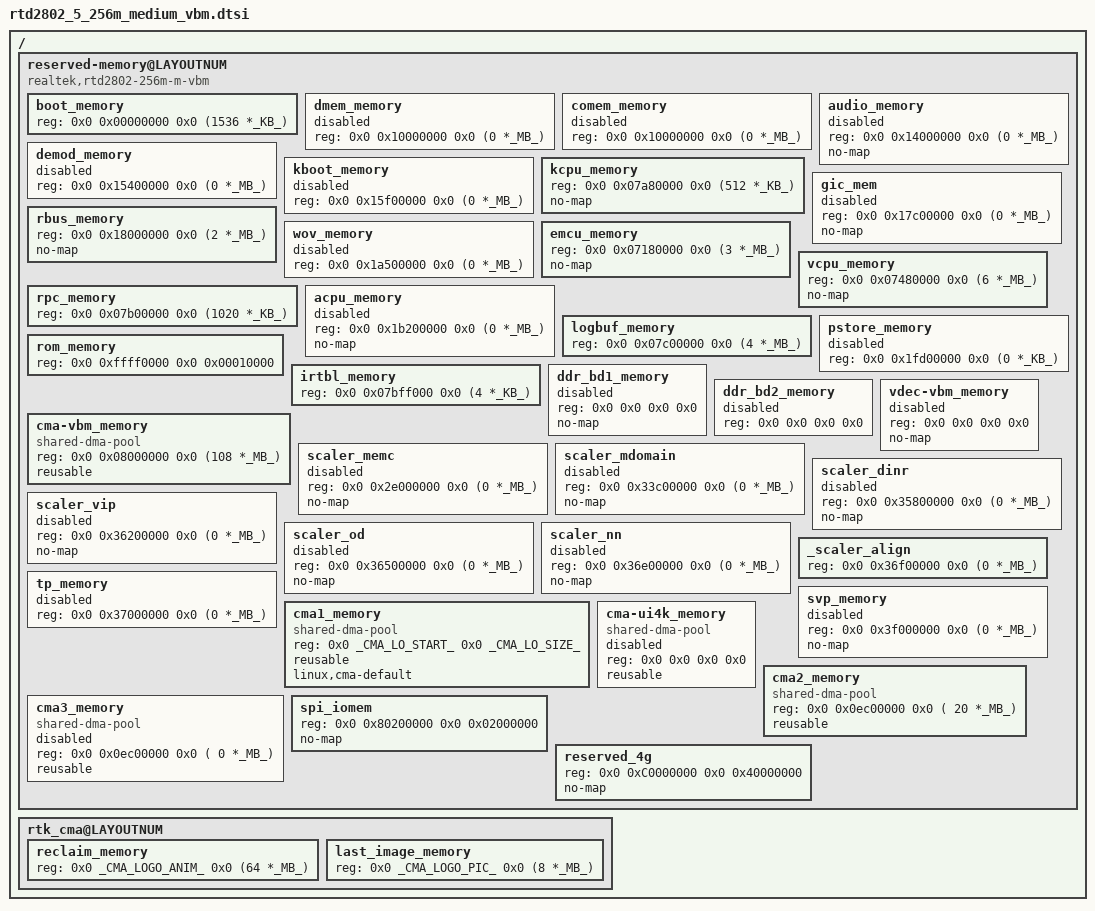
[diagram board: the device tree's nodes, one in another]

// Ref:
//  https://source.android.com/devices/architecture/dto/syntax


/ {
	reserved-memory@LAYOUTNUM {
		#address-cells = <2>;
		#size-cells = <2>;
		ranges;

		// devicetree identification board & overlay info
		compatible = "realtek,rtd2802-256m-m-vbm", "realtek,rtd2802";


		boot_memory {                       reg = <0x0 0x00000000 0x0 (1536 *_KB_)>;
		};

		dmem_memory {                       reg = <0x0 0x10000000 0x0 (0    *_MB_)>;
			status = "disabled";
			/* BAN_NORMAL if size */
		};

		comem_memory {                      reg = <0x0 0x10000000 0x0 (0    *_MB_)>;
			status = "disabled";
		};

		audio_memory {                      reg = <0x0 0x14000000 0x0 (0   *_MB_)>;
			no-map;
			status = "disabled";
		};

		demod_memory {                      reg = <0x0 0x15400000 0x0 (0    *_MB_)>;
			status = "disabled";
		};

		kboot_memory {                      reg = <0x0 0x15f00000 0x0 (0    *_MB_)>;
			status = "disabled"; // it's 0 at rmm.c
		};

		/* ATF */
		kcpu_memory {                       reg = <0x0 0x07a80000 0x0 (512   *_KB_)>;
			no-map;
		};

		gic_mem {                           reg = <0x0 0x17c00000 0x0 (0    *_MB_)>; // HW FIXED
			no-map;
			status = "disabled";
		};

		rbus_memory {                       reg = <0x0 0x18000000 0x0 (2    *_MB_)>; // HW FIXED
			no-map;
		};

		wov_memory {                        reg = <0x0 0x1a500000 0x0 (0    *_MB_)>;
			status = "disabled";
		};

		emcu_memory {                       reg = <0x0 0x07180000 0x0 (3    *_MB_)>;
			no-map;
		};

		vcpu_memory {                       reg = <0x0 0x07480000 0x0 (6    *_MB_)>;
			no-map;
		};

		rpc_memory {                        reg = <0x0 0x07b00000 0x0 (1020  *_KB_)>;
		};

		acpu_memory {                       reg = <0x0 0x1b200000 0x0 (0   *_MB_)>;
			no-map;
			status = "disabled";
		};

		/* The maximum reserved space for logbuf */
		logbuf_memory {                     reg = <0x0 0x07c00000 0x0 (4    *_MB_)>;
		};

		rom_memory {                        reg = <0x0 0xffff0000 0x0 0x00010000>;
		};

		pstore_memory {                     reg = <0x0 0x1fd00000 0x0 (0   *_KB_)>;
			status = "disabled";
		};

		irtbl_memory {                      reg = <0x0 0x07bff000 0x0 (4    *_KB_)>;
		};

		ddr_bd1_memory {                    reg = <0x0 0x0 0x0 0x0>;
			status = "disabled";
			no-map;
			/* BAN_NOT_USED if ddr_swap */
		};
		ddr_bd2_memory {                    reg = <0x0 0x0 0x0 0x0>;
			status = "disabled";
			/* BAN_NOT_USED if size */
		};

		// CARVEDOUT_VDEC_VBM
		// (paired with ...CARVEOUT_HEAP_CHUNK_SIZE)
		vdec-vbm_memory {                   reg = <0x0 0x0 0x0 0x0>;
			no-map; // VDEC_VBM(remove)

			status = "disabled";
		};

		// CARVEDOUT_CMA_VBM
		// (paired with VBM_HEAP_...CHUNK_SIZE)
		cma-vbm_memory  {                   reg = <0x0 0x08000000 0x0 (108  *_MB_)>;
			/* no-map; */ // VDEC_VBM(remove), CMA_VBM(reserve)

			compatible = "shared-dma-pool"; // CMA_VBM(reserve)
			reusable;
		};

		scaler_memc {                       reg = <0x0 0x2e000000 0x0 (0   *_MB_)>;
			no-map;
			status = "disabled";
		};

		scaler_mdomain {                    reg = <0x0 0x33c00000 0x0 (0   *_MB_)>;
			no-map;
			status = "disabled";
		};

		scaler_dinr {                       reg = <0x0 0x35800000 0x0 (0   *_MB_)>;
			no-map;
			status = "disabled";
		};

		scaler_vip {                        reg = <0x0 0x36200000 0x0 (0    *_MB_)>;
			no-map;
			status = "disabled";
		};

		scaler_od {                         reg = <0x0 0x36500000 0x0 (0    *_MB_)>;
			no-map;
			status = "disabled";
		};

		scaler_nn {                         reg = <0x0 0x36e00000 0x0 (0    *_MB_)>;
			no-map;
			status = "disabled";
		};
		_scaler_align {                     reg = <0x0 0x36f00000 0x0 (0    *_MB_)>; // ??? scaler reserve 4MB-aligned ???
		};

		tp_memory {                         reg = <0x0 0x37000000 0x0 (0   *_MB_)>;
			//no-map;
			status = "disabled";
		};

		// CARVEDOUT_GPU_RESERVED


		// CARVEDOUT_VDEC_RINGBUF
		svp_memory {                        reg = <0x0 0x3f000000 0x0 (0   *_MB_)>;
			no-map;
			status = "disabled";
		};

		// CARVEDOUT_CMA_LOW
		cma1_memory {                       reg = <0x0 _CMA_LO_START_ 0x0 _CMA_LO_SIZE_>;
			compatible = "shared-dma-pool";
			reusable;
#ifndef CONFIG_REALTEK_MEMORY_MANAGEMENT_MODULE
			linux,cma-default;
#endif
		};

		// CARVEDOUT_CMA_HIGH
		// CARVEDOUT_CMA_GPU_4K
		/*
		 * if UI_4K, CMA_GPU_4K use an exclusive region from original CMA2
		 */
		cma-ui4k_memory {                   reg = <0x0 0x0 0x0 0x0>;
			compatible = "shared-dma-pool";
			reusable;
			status = "disabled";
		};
		cma2_memory {                       reg = <0x0 0x0ec00000 0x0 ( 20 *_MB_)>;
			compatible = "shared-dma-pool";
			reusable;
		};

		// CARVEDOUT_CMA_3
		cma3_memory {                       reg = <0x0 0x0ec00000 0x0 ( 0   *_MB_)>;
			compatible = "shared-dma-pool";
			reusable;
			status = "disabled";
		};
		
		// CARVEDOUT_CMA_LOW_LIMIT
		// CARVEDOUT_CMA_BW


		spi_iomem {                         reg = <0x0 0x80200000 0x0 0x02000000>; // HW FIXED
			no-map;
		};

		// for those less than 4G, prevent them touching 4G addr space
		// especially for those like fixed 2G rescue, or hacked 2G
		reserved_4g {                       reg = <0x0 0xC0000000 0x0 0x40000000>;
			no-map;
		};

	};


	rtk_cma@LAYOUTNUM {
		/*
		 * early reserve of cma1_memory
		 */

		#address-cells = <2>;
		#size-cells = <2>;

		reclaim_memory {                    reg = <0x0 _CMA_LOGO_ANIM_ 0x0 (64   *_MB_)>;
		};

		last_image_memory {                 reg = <0x0 _CMA_LOGO_PIC_  0x0 (8    *_MB_)>;
		};
	};
};

